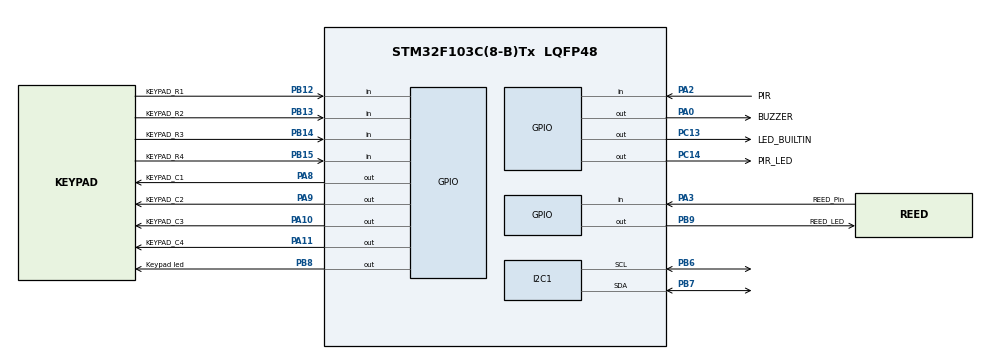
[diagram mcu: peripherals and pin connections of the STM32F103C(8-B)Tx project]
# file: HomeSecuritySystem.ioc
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FREERTOS.Tasks01=defaultTask,24,128,StartDefaultTask,Default,NULL,Dynamic,NULL,NULL
Mcu.Family=STM32F1
Mcu.Name=STM32F103C(8-B)Tx
Mcu.Package=LQFP48
NVIC.PriorityGroup=NVIC_PRIORITYGROUP_4
NVIC.TIM1_UP_IRQn=true\:15\:0\:false\:false\:true\:false\:false\:true\:true
NVIC.TimeBase=TIM1_UP_IRQn
NVIC.TimeBaseIP=TIM1
PA0-WKUP.GPIO_Label=BUZZER
PA0-WKUP.Signal=GPIO_Output
PA10.GPIO_Label=KEYPAD_C3
PA10.PinState=GPIO_PIN_SET
PA10.Signal=GPIO_Output
PA11.GPIO_Label=KEYPAD_C4
PA11.PinState=GPIO_PIN_SET
PA11.Signal=GPIO_Output
PA13.Mode=Serial_Wire
PA13.Signal=SYS_JTMS-SWDIO
PA14.Mode=Serial_Wire
PA14.Signal=SYS_JTCK-SWCLK
PA2.GPIO_Label=PIR
PA2.Signal=GPIO_Input
PA3.GPIO_Label=REED_Pin
PA3.GPIO_PuPd=GPIO_PULLUP
PA3.Signal=GPIO_Input
PA8.GPIO_Label=KEYPAD_C1
PA8.GPIO_ModeDefaultOutputPP=GPIO_MODE_OUTPUT_PP
PA8.GPIO_PuPd=GPIO_NOPULL
PA8.PinState=GPIO_PIN_SET
PA8.Signal=GPIO_Output
PA9.GPIO_Label=KEYPAD_C2
PA9.GPIO_ModeDefaultOutputPP=GPIO_MODE_OUTPUT_PP
PA9.PinState=GPIO_PIN_SET
PA9.Signal=GPIO_Output
PB12.GPIO_Label=KEYPAD_R1
PB12.GPIO_Mode=GPIO_MODE_INPUT
PB12.GPIO_PuPd=GPIO_PULLUP
PB12.Signal=GPIO_Input
PB13.GPIO_Label=KEYPAD_R2
PB13.GPIO_PuPd=GPIO_PULLUP
PB13.Signal=GPIO_Input
PB14.GPIO_Label=KEYPAD_R3
PB14.GPIO_PuPd=GPIO_PULLUP
PB14.Signal=GPIO_Input
PB15.GPIO_Label=KEYPAD_R4
PB15.GPIO_PuPd=GPIO_PULLUP
PB15.Signal=GPIO_Input
PB6.Mode=I2C
PB6.Signal=I2C1_SCL
PB7.Mode=I2C
PB7.Signal=I2C1_SDA
PB8.GPIO_Label=Keypad led
PB8.Signal=GPIO_Output
PB9.GPIO_Label=REED_LED
PB9.Signal=GPIO_Output
PC13-TAMPER-RTC.GPIO_Label=LED_BUILTIN
PC13-TAMPER-RTC.PinState=GPIO_PIN_SET
PC13-TAMPER-RTC.Signal=GPIO_Output
PC14-OSC32_IN.GPIO_Label=PIR_LED
PC14-OSC32_IN.Signal=GPIO_Output
ProjectManager.HeapSize=0x200
ProjectManager.StackSize=0x400
ProjectManager.TargetToolchain=CMake
RCC.APB1Freq_Value=8000000
RCC.APB2Freq_Value=8000000
VP_FREERTOS_VS_CMSIS_V2.Mode=CMSIS_V2
VP_SYS_VS_tim1.Mode=TIM1
board=custom

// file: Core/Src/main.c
/* USER CODE BEGIN Header */
/**
  ******************************************************************************
  * @file           : main.c
  * @brief          : Main program body
  ******************************************************************************
  */
/* USER CODE END Header */
#include "main.h"
#include "cmsis_os.h"

/* USER CODE BEGIN Includes */
#include "security_task.h"
#include "keypad_task.h"
#include "buzzer_task.h"
#include "lcd.h"
#include "pir_task.h"
#include "reed_task.h"

/* USER CODE END Includes */

I2C_HandleTypeDef hi2c1;

/* Definitions for defaultTask */
osThreadId_t defaultTaskHandle;
const osThreadAttr_t defaultTask_attributes = {
  .name = "defaultTask",
  .stack_size = 128 * 4,
  .priority = (osPriority_t) osPriorityNormal,
};
/* USER CODE BEGIN PV */
osMessageQueueId_t keypadQueue;
osMessageQueueId_t buzzerQueue;
/* USER CODE END PV */

void SystemClock_Config(void);
static void MX_GPIO_Init(void);
static void MX_I2C1_Init(void);
void StartDefaultTask(void *argument);

int main(void)
{

  /* MCU Configuration--------------------------------------------------------*/

  /* Reset of all peripherals, Initializes the Flash interface and the Systick. */
  HAL_Init();

  /* Configure the system clock */
  SystemClock_Config();

  /* Initialize all configured peripherals */
  MX_GPIO_Init();
  MX_I2C1_Init();
  /* USER CODE BEGIN 2 */
  LCD_Init();

  /* USER CODE END 2 */

  /* Init scheduler */
  osKernelInitialize();

  /* Create the thread(s) */
  /* creation of defaultTask */
  defaultTaskHandle = osThreadNew(StartDefaultTask, NULL, &defaultTask_attributes);

  /* USER CODE BEGIN RTOS_THREADS */
  /* add threads, ... */
  /* USER CODE BEGIN RTOS_THREADS */

  buzzerQueue = BuzzerTask_Init();

  keypadQueue = SecurityTask_Init(buzzerQueue);

  KeypadTask_Init(keypadQueue);
  PIRTask_Init();
  ReedTask_Init();
  /* USER CODE END RTOS_THREADS */

  /* Start scheduler */
  osKernelStart();

  /* We should never get here as control is now taken by the scheduler */

  /* Infinite loop */
  while (1)
  {

  }
}

void SystemClock_Config(void)
{
  RCC_OscInitTypeDef RCC_OscInitStruct = {0};
  RCC_ClkInitTypeDef RCC_ClkInitStruct = {0};

  /** Initializes the RCC Oscillators according to the specified parameters
  * in the RCC_OscInitTypeDef structure.
  */
  RCC_OscInitStruct.OscillatorType = RCC_OSCILLATORTYPE_HSI;
  RCC_OscInitStruct.HSIState = RCC_HSI_ON;
  RCC_OscInitStruct.HSICalibrationValue = RCC_HSICALIBRATION_DEFAULT;
  RCC_OscInitStruct.PLL.PLLState = RCC_PLL_NONE;
  if (HAL_RCC_OscConfig(&RCC_OscInitStruct) != HAL_OK)
  {
    Error_Handler();
  }

  /** Initializes the CPU, AHB and APB buses clocks
  */
  RCC_ClkInitStruct.ClockType = RCC_CLOCKTYPE_HCLK|RCC_CLOCKTYPE_SYSCLK
                              |RCC_CLOCKTYPE_PCLK1|RCC_CLOCKTYPE_PCLK2;
  RCC_ClkInitStruct.SYSCLKSource = RCC_SYSCLKSOURCE_HSI;
  RCC_ClkInitStruct.AHBCLKDivider = RCC_SYSCLK_DIV1;
  RCC_ClkInitStruct.APB1CLKDivider = RCC_HCLK_DIV1;
  RCC_ClkInitStruct.APB2CLKDivider = RCC_HCLK_DIV1;

  if (HAL_RCC_ClockConfig(&RCC_ClkInitStruct, FLASH_LATENCY_0) != HAL_OK)
  {
    Error_Handler();
  }
}

static void MX_I2C1_Init(void)
{

  hi2c1.Instance = I2C1;
  hi2c1.Init.ClockSpeed = 100000;
  hi2c1.Init.DutyCycle = I2C_DUTYCYCLE_2;
  hi2c1.Init.OwnAddress1 = 0;
  hi2c1.Init.AddressingMode = I2C_ADDRESSINGMODE_7BIT;
  hi2c1.Init.DualAddressMode = I2C_DUALADDRESS_DISABLE;
  hi2c1.Init.OwnAddress2 = 0;
  hi2c1.Init.GeneralCallMode = I2C_GENERALCALL_DISABLE;
  hi2c1.Init.NoStretchMode = I2C_NOSTRETCH_DISABLE;
  if (HAL_I2C_Init(&hi2c1) != HAL_OK)
  {
    Error_Handler();
  }

}

static void MX_GPIO_Init(void)
{
  GPIO_InitTypeDef GPIO_InitStruct = {0};

  /* GPIO Ports Clock Enable */
  __HAL_RCC_GPIOC_CLK_ENABLE();
  __HAL_RCC_GPIOA_CLK_ENABLE();
  __HAL_RCC_GPIOB_CLK_ENABLE();

  /*Configure GPIO pin Output Level */
  HAL_GPIO_WritePin(LED_BUILTIN_GPIO_Port, LED_BUILTIN_Pin, GPIO_PIN_SET);

  /*Configure GPIO pin Output Level */
  HAL_GPIO_WritePin(PIR_LED_GPIO_Port, PIR_LED_Pin, GPIO_PIN_RESET);

  /*Configure GPIO pin Output Level */
  HAL_GPIO_WritePin(BUZZER_GPIO_Port, BUZZER_Pin, GPIO_PIN_RESET);

  /*Configure GPIO pin Output Level */
  HAL_GPIO_WritePin(GPIOA, KEYPAD_C1_Pin|KEYPAD_C2_Pin|KEYPAD_C3_Pin|KEYPAD_C4_Pin, GPIO_PIN_SET);

  /*Configure GPIO pin Output Level */
  HAL_GPIO_WritePin(GPIOB, Keypad_led_Pin|REED_LED_Pin, GPIO_PIN_RESET);

  /*Configure GPIO pins : LED_BUILTIN_Pin PIR_LED_Pin */
  GPIO_InitStruct.Pin = LED_BUILTIN_Pin|PIR_LED_Pin;
  GPIO_InitStruct.Mode = GPIO_MODE_OUTPUT_PP;
  GPIO_InitStruct.Pull = GPIO_NOPULL;
  GPIO_InitStruct.Speed = GPIO_SPEED_FREQ_LOW;
  HAL_GPIO_Init(GPIOC, &GPIO_InitStruct);

  /*Configure GPIO pins : BUZZER_Pin KEYPAD_C1_Pin KEYPAD_C2_Pin KEYPAD_C3_Pin
                           KEYPAD_C4_Pin */
  GPIO_InitStruct.Pin = BUZZER_Pin|KEYPAD_C1_Pin|KEYPAD_C2_Pin|KEYPAD_C3_Pin
                          |KEYPAD_C4_Pin;
  GPIO_InitStruct.Mode = GPIO_MODE_OUTPUT_PP;
  GPIO_InitStruct.Pull = GPIO_NOPULL;
  GPIO_InitStruct.Speed = GPIO_SPEED_FREQ_LOW;
  HAL_GPIO_Init(GPIOA, &GPIO_InitStruct);

  /*Configure GPIO pin : PIR_Pin */
  GPIO_InitStruct.Pin = PIR_Pin;
  GPIO_InitStruct.Mode = GPIO_MODE_INPUT;
  GPIO_InitStruct.Pull = GPIO_NOPULL;
  HAL_GPIO_Init(PIR_GPIO_Port, &GPIO_InitStruct);

  /*Configure GPIO pin : REED_Pin_Pin */
  GPIO_InitStruct.Pin = REED_Pin_Pin;
  GPIO_InitStruct.Mode = GPIO_MODE_INPUT;
  GPIO_InitStruct.Pull = GPIO_PULLUP;
  HAL_GPIO_Init(REED_Pin_GPIO_Port, &GPIO_InitStruct);

  /*Configure GPIO pins : KEYPAD_R1_Pin KEYPAD_R2_Pin KEYPAD_R3_Pin KEYPAD_R4_Pin */
  GPIO_InitStruct.Pin = KEYPAD_R1_Pin|KEYPAD_R2_Pin|KEYPAD_R3_Pin|KEYPAD_R4_Pin;
  GPIO_InitStruct.Mode = GPIO_MODE_INPUT;
  GPIO_InitStruct.Pull = GPIO_PULLUP;
  HAL_GPIO_Init(GPIOB, &GPIO_InitStruct);

  /*Configure GPIO pins : Keypad_led_Pin REED_LED_Pin */
  GPIO_InitStruct.Pin = Keypad_led_Pin|REED_LED_Pin;
  GPIO_InitStruct.Mode = GPIO_MODE_OUTPUT_PP;
  GPIO_InitStruct.Pull = GPIO_NOPULL;
  GPIO_InitStruct.Speed = GPIO_SPEED_FREQ_LOW;
  HAL_GPIO_Init(GPIOB, &GPIO_InitStruct);

}

void StartDefaultTask(void *argument)
{
  for(;;)
  {
    osDelay(1);
  }
}

void HAL_TIM_PeriodElapsedCallback(TIM_HandleTypeDef *htim)
{
  if (htim->Instance == TIM1)
  {
    HAL_IncTick();
  }
}

void Error_Handler(void)
{
  __disable_irq();
  while (1)
  {
  }
}
